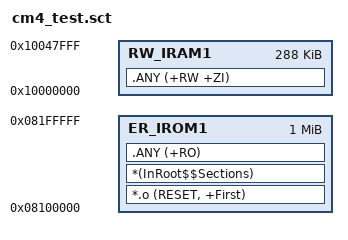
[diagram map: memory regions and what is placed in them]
LR_IROM1 0x08100000 0x00100000
{
    ER_IROM1 0x08100000 0x00100000
    {
        *.o (RESET, +First)
        *(InRoot$$Sections)
        .ANY (+RO)
    }
    RW_IRAM1 0x10000000 0x00048000
    {
        .ANY (+RW +ZI)
    }
}
